# OCP_SOCKET_PRM register map
Vendor: Texas Instruments
Peripheral module from a debugger description file (folder TDA3x).
Registers are 32-bit, access per field, reset 0x0 unless marked. A register's access mark holds for its fields unless they carry their own. Offsets are as the file gives them; lines under a group give offsets from that group; [hi:lo] are bit positions; {n}, {i} and the like mark numbered series; 'fields as' and 'values as' point back to an identical list; <NAME> marks a mode.

## OCP_SOCKET_PRM
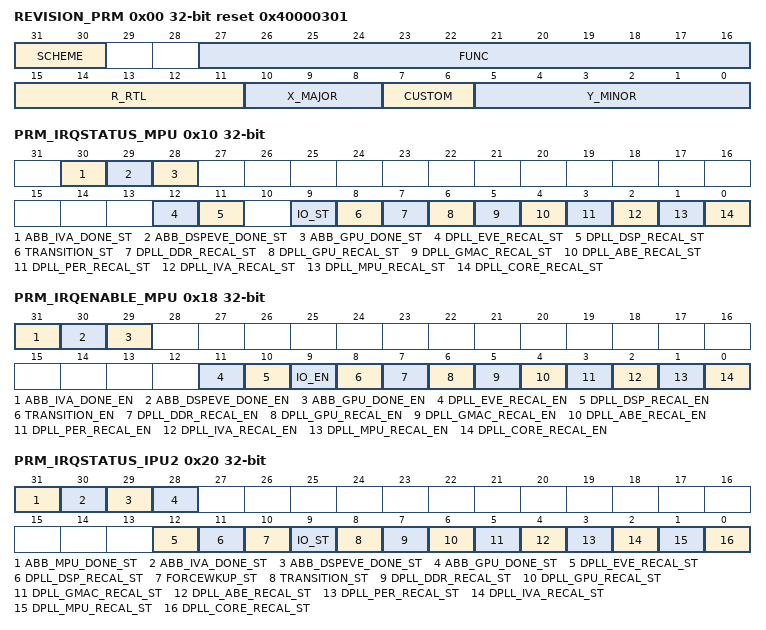
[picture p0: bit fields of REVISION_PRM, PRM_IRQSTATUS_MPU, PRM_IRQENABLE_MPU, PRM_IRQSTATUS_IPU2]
0x00 REVISION_PRM ro reset 0x40000301 — This register contains the IP revision code for the PRM part of the PRCM
  [31:30] SCHEME
  [27:16] FUNC — Function indicates a software compatible module family.
  [15:11] R_RTL — RTL Version (R)
  [10:8] X_MAJOR — Major Revision (X)
  [7:6] CUSTOM — Indicates a special version for a particular device.
    0=STANDARD (Non custom (standard) revision)
  [5:0] Y_MINOR — Minor Revision (Y)
0x10 PRM_IRQSTATUS_MPU — This register provides status on MPU interrupt events. Any event is logged independently of the corresponding IRQENABLE value. SW is required to clear a set bit by writing a '1' into the bit-position to be cleared.
  [all] fields
    0=IRQ_FAL (No interrupt); 1=IRQ_TRU (Interrupt is pending)
  [30] ABB_IVA_DONE_ST rw — IVA ABB mode change completion status. This status is set for both automatic transition upon a voltage transition, and OPP change (when OPP_CHANGE bit is cleared by hardware in PRM_ABBLDO_MM_CTRL register). It is cleared by SW.
  [29] ABB_DSPEVE_DONE_ST rw — DSPEVE ABB mode change completion status. This status is set for both automatic transition upon a voltage transition, and OPP change (when OPP_CHANGE bit is cleared by hardware in PRM_ABBLDO_MM_CTRL register). It is cleared by SW.
  [28] ABB_GPU_DONE_ST rw — GPU ABB mode change completion status. This status is set for both automatic transition upon a voltage transition, and OPP change (when OPP_CHANGE bit is cleared by hardware in PRM_ABBLDO_MM_CTRL register). It is cleared by SW.
  [12] DPLL_EVE_RECAL_ST rw — EVE DPLL recalibration interrupt status.
  [11] DPLL_DSP_RECAL_ST rw — DSP DPLL recalibration interrupt status.
  [9] IO_ST rw — IO pad event interrupt status.
  [8] TRANSITION_ST rw — Software supervised transition completed event interrupt status (any domain). Asserted upon completion of any clock domain force wakeup transition or upon completion of any power domain sleep transition with at least one enclosed clock domain configured in forced-sleep.
  [7] DPLL_DDR_RECAL_ST rw — DDR DPLL recalibration interrupt status.
  [6] DPLL_GPU_RECAL_ST rw — GPU DPLL recalibration interrupt status.
  [5] DPLL_GMAC_RECAL_ST rw — GMAC DPLL recalibration interrupt status.
  [4] DPLL_ABE_RECAL_ST rw — ABE DPLL recalibration interrupt status.
  [3] DPLL_PER_RECAL_ST rw — PER DPLL recalibration interrupt status.
  [2] DPLL_IVA_RECAL_ST rw — IVA DPLL recalibration interrupt status.
  [1] DPLL_MPU_RECAL_ST rw — MPU DPLL recalibration interrupt status.
  [0] DPLL_CORE_RECAL_ST rw — CORE DPLL recalibration interrupt status.
0x14 PRM_IRQSTATUS_MPU_2 — This register provides status on MPU interrupt events. Any event is logged independently of the corresponding IRQENABLE value. SW is required to clear a set bit by writing a '1' into the bit-position to be cleared.
  [7] ABB_MPU_DONE_ST rw — MPU ABB mode change completion status. This status is set for both automatic transition upon a voltage transition, and OPP change (when OPP_CHANGE bit is cleared by hardware in PRM_ABBLDO_MPU_CTRL register). It is cleared by SW.
    0=IRQ_FAL (No interrupt); 1=IRQ_TRU (Interrupt is pending)
0x18 PRM_IRQENABLE_MPU — This register is used to enable or disable MPU interrupt activation upon presence of corresponding IRQSTATUS bit.
  [31] ABB_IVA_DONE_EN rw — IVA ABB mode change done enable
    0=IRQ_FAL (No interrupt); 1=IRQ_TRU (Interrupt is pending)
  [30] ABB_DSPEVE_DONE_EN rw — DSPEVE ABB mode change done enable
    0=IRQ_FAL (No interrupt); 1=IRQ_TRU (Interrupt is pending)
  [29] ABB_GPU_DONE_EN rw — GPU ABB mode change done enable
    0=IRQ_FAL (No interrupt); 1=IRQ_TRU (Interrupt is pending)
  [11] DPLL_EVE_RECAL_EN rw — EVE DPLL recalibration interrupt enable
    0=IRQ_MSK (Interrupt is masked); 1=IRQ_EN (Interrupt is enabled)
  [10] DPLL_DSP_RECAL_EN rw — DSP DPLL recalibration interrupt enable
    values as DPLL_EVE_RECAL_EN
  [9] IO_EN rw — IO pad event interrupt enable
    values as DPLL_EVE_RECAL_EN
  [8] TRANSITION_EN rw — Software supervised transition completed event interrupt enable (any domain)
    values as DPLL_EVE_RECAL_EN
  [7] DPLL_DDR_RECAL_EN rw — DDR DPLL recalibration interrupt enable
    values as DPLL_EVE_RECAL_EN
  [6] DPLL_GPU_RECAL_EN rw — GPU DPLL recalibration interrupt enable
    values as DPLL_EVE_RECAL_EN
  [5] DPLL_GMAC_RECAL_EN rw — GMAC DPLL recalibration interrupt enable
    values as DPLL_EVE_RECAL_EN
  [4] DPLL_ABE_RECAL_EN rw — ABEDPLL recalibration interrupt enable
    values as DPLL_EVE_RECAL_EN
  [3] DPLL_PER_RECAL_EN rw — PER DPLL recalibration interrupt enable
    values as DPLL_EVE_RECAL_EN
  [2] DPLL_IVA_RECAL_EN rw — IVA DPLL recalibration interrupt enable
    values as DPLL_EVE_RECAL_EN
  [1] DPLL_MPU_RECAL_EN rw — MPU DPLL recalibration interrupt enable
    values as DPLL_EVE_RECAL_EN
  [0] DPLL_CORE_RECAL_EN rw — CORE DPLL recalibration interrupt enable
    values as DPLL_EVE_RECAL_EN
0x1C PRM_IRQENABLE_MPU_2 — This register is used to enable or disable MPU interrupt activation upon presence of corresponding IRQSTATUS bit.
  [7] ABB_MPU_DONE_EN rw — MPU ABB mode change done enable
    0=IRQ_FAL (No interrupt); 1=IRQ_TRU (Interrupt is pending)
0x20 PRM_IRQSTATUS_IPU2 — This register provides status on IPU2 interrupt events. Any event is logged independently of the corresponding IRQENABLE value. SW is required to clear a set bit by writing a '1' into the bit-position to be cleared.
  [all] fields
    0=IRQ_FAL (No interrupt); 1=IRQ_TRU (Interrupt is pending)
  [31] ABB_MPU_DONE_ST rw — MPU ABB mode change completion status. This status is set for both automatic transition upon a voltage transition, and OPP change (when OPP_CHANGE bit is cleared by hardware in PRM_ABBLDO_MM_CTRL register). It is cleared by SW.
  [30] ABB_IVA_DONE_ST rw — IVA ABB mode change completion status. This status is set for both automatic transition upon a voltage transition, and OPP change (when OPP_CHANGE bit is cleared by hardware in PRM_ABBLDO_MM_CTRL register). It is cleared by SW.
  [29] ABB_DSPEVE_DONE_ST rw — DSPEVE ABB mode change completion status. This status is set for both automatic transition upon a voltage transition, and OPP change (when OPP_CHANGE bit is cleared by hardware in PRM_ABBLDO_MM_CTRL register). It is cleared by SW.
  [28] ABB_GPU_DONE_ST rw — GPU ABB mode change completion status. This status is set for both automatic transition upon a voltage transition, and OPP change (when OPP_CHANGE bit is cleared by hardware in PRM_ABBLDO_MM_CTRL register). It is cleared by SW.
  [12] DPLL_EVE_RECAL_ST rw — EVE DPLL recalibration interrupt status.
  [11] DPLL_DSP_RECAL_ST rw — DSP DPLL recalibration interrupt status.
  [10] FORCEWKUP_ST rw — IPU domain software supervised wakeup transition completed event interrupt status.
  [9] IO_ST rw — IO pad event interrupt status.
  [8] TRANSITION_ST rw — Software supervised transition completed event interrupt status (any domain). Asserted upon completion of any clock domain force wakeup transition or upon completion of any power domain sleep transition with at least one enclosed clock domain configured in forced-sleep.
  [7] DPLL_DDR_RECAL_ST rw — DDR DPLL recalibration interrupt status.
  [6] DPLL_GPU_RECAL_ST rw — GPU DPLL recalibration interrupt status.
  [5] DPLL_GMAC_RECAL_ST rw — GMAC DPLL recalibration interrupt status.
  [4] DPLL_ABE_RECAL_ST rw — ABE DPLL recalibration interrupt status.
  [3] DPLL_PER_RECAL_ST rw — PER DPLL recalibration interrupt status.
  [2] DPLL_IVA_RECAL_ST rw — IVA DPLL recalibration interrupt status.
  [1] DPLL_MPU_RECAL_ST rw — MPU DPLL recalibration interrupt status.
  [0] DPLL_CORE_RECAL_ST rw — CORE DPLL recalibration interrupt status.
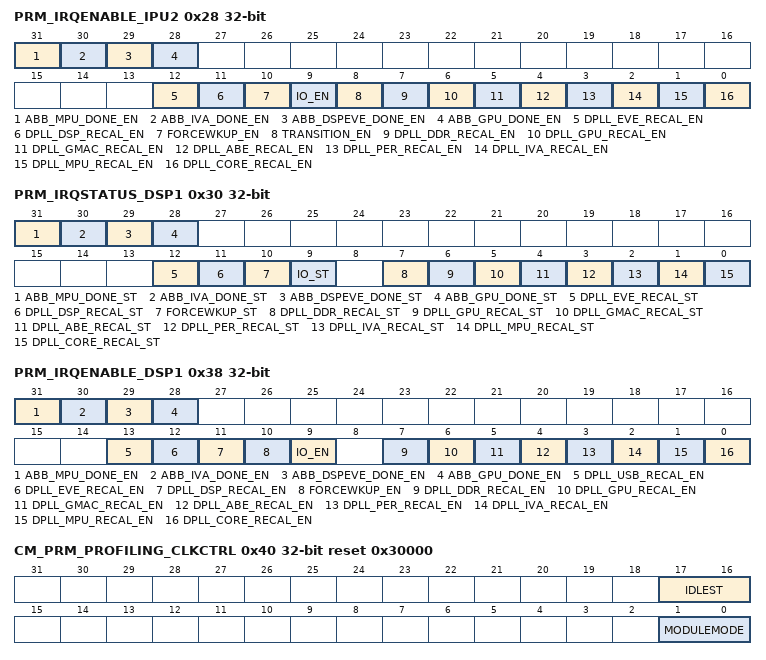
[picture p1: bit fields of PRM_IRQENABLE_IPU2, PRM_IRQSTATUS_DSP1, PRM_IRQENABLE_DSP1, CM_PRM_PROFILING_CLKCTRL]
0x28 PRM_IRQENABLE_IPU2 — This register is used to enable or disable IPU2 interrupt activation upon presence of corresponding IRQSTATUS bit.
  [31] ABB_MPU_DONE_EN rw — MPU ABB mode change done enable
    0=IRQ_FAL (No interrupt); 1=IRQ_TRU (Interrupt is pending)
  [30] ABB_IVA_DONE_EN rw — IVA ABB mode change done enable
    0=IRQ_FAL (No interrupt); 1=IRQ_TRU (Interrupt is pending)
  [29] ABB_DSPEVE_DONE_EN rw — DSPEVE ABB mode change done enable
    0=IRQ_FAL (No interrupt); 1=IRQ_TRU (Interrupt is pending)
  [28] ABB_GPU_DONE_EN rw — GPU ABB mode change done enable
    0=IRQ_FAL (No interrupt); 1=IRQ_TRU (Interrupt is pending)
  [12] DPLL_EVE_RECAL_EN rw — EVE DPLL recalibration interrupt enable
    values as PRM_IRQENABLE_MPU.DPLL_EVE_RECAL_EN
  [11] DPLL_DSP_RECAL_EN rw — DSP DPLL recalibration interrupt enable
    values as PRM_IRQENABLE_MPU.DPLL_EVE_RECAL_EN
  [10] FORCEWKUP_EN rw — IPU domain software supervised wakeup transition completed event interrupt enable.
    values as PRM_IRQENABLE_MPU.DPLL_EVE_RECAL_EN
  [9] IO_EN rw — IO pad event interrupt enable
    values as PRM_IRQENABLE_MPU.DPLL_EVE_RECAL_EN
  [8] TRANSITION_EN rw — Software supervised transition completed event interrupt enable (any domain)
    values as PRM_IRQENABLE_MPU.DPLL_EVE_RECAL_EN
  [7] DPLL_DDR_RECAL_EN rw — DDR DPLL recalibration interrupt enable
    values as PRM_IRQENABLE_MPU.DPLL_EVE_RECAL_EN
  [6] DPLL_GPU_RECAL_EN rw — GPU DPLL recalibration interrupt enable
    values as PRM_IRQENABLE_MPU.DPLL_EVE_RECAL_EN
  [5] DPLL_GMAC_RECAL_EN rw — GMAC DPLL recalibration interrupt enable
    values as PRM_IRQENABLE_MPU.DPLL_EVE_RECAL_EN
  [4] DPLL_ABE_RECAL_EN rw — ABEDPLL recalibration interrupt enable
    values as PRM_IRQENABLE_MPU.DPLL_EVE_RECAL_EN
  [3] DPLL_PER_RECAL_EN rw — PER DPLL recalibration interrupt enable
    values as PRM_IRQENABLE_MPU.DPLL_EVE_RECAL_EN
  [2] DPLL_IVA_RECAL_EN rw — IVA DPLL recalibration interrupt enable
    values as PRM_IRQENABLE_MPU.DPLL_EVE_RECAL_EN
  [1] DPLL_MPU_RECAL_EN rw — MPU DPLL recalibration interrupt enable
    values as PRM_IRQENABLE_MPU.DPLL_EVE_RECAL_EN
  [0] DPLL_CORE_RECAL_EN rw — CORE DPLL recalibration interrupt enable
    values as PRM_IRQENABLE_MPU.DPLL_EVE_RECAL_EN
0x30 PRM_IRQSTATUS_DSP1 — This register provides status on DSP1 interrupt events. Any event is logged independently of the corresponding IRQENABLE value. SW is required to clear a set bit by writing a '1' into the bit-position to be cleared.
  [all] fields
    0=IRQ_FAL (No interrupt); 1=IRQ_TRU (Interrupt is pending)
  [31] ABB_MPU_DONE_ST rw — MPU ABB mode change completion status. This status is set for both automatic transition upon a voltage transition, and OPP change (when OPP_CHANGE bit is cleared by hardware in PRM_ABBLDO_MM_CTRL register). It is cleared by SW.
  [30] ABB_IVA_DONE_ST rw — IVA ABB mode change completion status. This status is set for both automatic transition upon a voltage transition, and OPP change (when OPP_CHANGE bit is cleared by hardware in PRM_ABBLDO_MM_CTRL register). It is cleared by SW.
  [29] ABB_DSPEVE_DONE_ST rw — DSPEVE ABB mode change completion status. This status is set for both automatic transition upon a voltage transition, and OPP change (when OPP_CHANGE bit is cleared by hardware in PRM_ABBLDO_MM_CTRL register). It is cleared by SW.
  [28] ABB_GPU_DONE_ST rw — GPU ABB mode change completion status. This status is set for both automatic transition upon a voltage transition, and OPP change (when OPP_CHANGE bit is cleared by hardware in PRM_ABBLDO_MM_CTRL register). It is cleared by SW.
  [12] DPLL_EVE_RECAL_ST rw — EVE DPLL recalibration interrupt status.
  [11] DPLL_DSP_RECAL_ST rw — DSP DPLL recalibration interrupt status.
  [10] FORCEWKUP_ST rw — IPU domain software supervised wakeup transition completed event interrupt status.
  [9] IO_ST rw — IO pad event interrupt status.
  [7] DPLL_DDR_RECAL_ST rw — DDR DPLL recalibration interrupt status.
  [6] DPLL_GPU_RECAL_ST rw — GPU DPLL recalibration interrupt status.
  [5] DPLL_GMAC_RECAL_ST rw — GMAC DPLL recalibration interrupt status.
  [4] DPLL_ABE_RECAL_ST rw — ABE DPLL recalibration interrupt status.
  [3] DPLL_PER_RECAL_ST rw — PER DPLL recalibration interrupt status.
  [2] DPLL_IVA_RECAL_ST rw — IVA DPLL recalibration interrupt status.
  [1] DPLL_MPU_RECAL_ST rw — MPU DPLL recalibration interrupt status.
  [0] DPLL_CORE_RECAL_ST rw — CORE DPLL recalibration interrupt status.
0x38 PRM_IRQENABLE_DSP1 — This register is used to enable or disable DSP1 interrupt activation upon presence of corresponding IRQSTATUS bit.
  [31] ABB_MPU_DONE_EN rw — MPU ABB mode change done enable
    0=IRQ_FAL (No interrupt); 1=IRQ_TRU (Interrupt is pending)
  [30] ABB_IVA_DONE_EN rw — IVA ABB mode change done enable
    0=IRQ_FAL (No interrupt); 1=IRQ_TRU (Interrupt is pending)
  [29] ABB_DSPEVE_DONE_EN rw — DSPEVE ABB mode change done enable
    0=IRQ_FAL (No interrupt); 1=IRQ_TRU (Interrupt is pending)
  [28] ABB_GPU_DONE_EN rw — GPU ABB mode change done enable
    0=IRQ_FAL (No interrupt); 1=IRQ_TRU (Interrupt is pending)
  [13] DPLL_USB_RECAL_EN rw — USB DPLL recalibration interrupt enable
    values as PRM_IRQENABLE_MPU.DPLL_EVE_RECAL_EN
  [12] DPLL_EVE_RECAL_EN rw — EVE DPLL recalibration interrupt enable
    values as PRM_IRQENABLE_MPU.DPLL_EVE_RECAL_EN
  [11] DPLL_DSP_RECAL_EN rw — DSP DPLL recalibration interrupt enable
    values as PRM_IRQENABLE_MPU.DPLL_EVE_RECAL_EN
  [10] FORCEWKUP_EN rw — IPU domain software supervised wakeup transition completed event interrupt enable.
    values as PRM_IRQENABLE_MPU.DPLL_EVE_RECAL_EN
  [9] IO_EN rw — IO pad event interrupt enable
    values as PRM_IRQENABLE_MPU.DPLL_EVE_RECAL_EN
  [7] DPLL_DDR_RECAL_EN rw — DDR DPLL recalibration interrupt enable
    values as PRM_IRQENABLE_MPU.DPLL_EVE_RECAL_EN
  [6] DPLL_GPU_RECAL_EN rw — GPU DPLL recalibration interrupt enable
    values as PRM_IRQENABLE_MPU.DPLL_EVE_RECAL_EN
  [5] DPLL_GMAC_RECAL_EN rw — GMAC DPLL recalibration interrupt enable
    values as PRM_IRQENABLE_MPU.DPLL_EVE_RECAL_EN
  [4] DPLL_ABE_RECAL_EN rw — ABEDPLL recalibration interrupt enable
    values as PRM_IRQENABLE_MPU.DPLL_EVE_RECAL_EN
  [3] DPLL_PER_RECAL_EN rw — PER DPLL recalibration interrupt enable
    values as PRM_IRQENABLE_MPU.DPLL_EVE_RECAL_EN
  [2] DPLL_IVA_RECAL_EN rw — IVA DPLL recalibration interrupt enable
    values as PRM_IRQENABLE_MPU.DPLL_EVE_RECAL_EN
  [1] DPLL_MPU_RECAL_EN rw — MPU DPLL recalibration interrupt enable
    values as PRM_IRQENABLE_MPU.DPLL_EVE_RECAL_EN
  [0] DPLL_CORE_RECAL_EN rw — CORE DPLL recalibration interrupt enable
    values as PRM_IRQENABLE_MPU.DPLL_EVE_RECAL_EN
0x40 CM_PRM_PROFILING_CLKCTRL reset 0x30000 — This register manages the PRM_PROFILING clock. [warm reset insensitive]
  [17:16] IDLEST ro — Module idle status
    0=FUNC (Module is fully functional); 1=TRANS (Module is performing transition: wakeup, or sleep, or sleep abortion); 2=IDLE (Module is in Idle); 3=DISABLE (Module is disabled)
  [1:0] MODULEMODE rw — Control the way mandatory clocks are managed.
    0=DISABLED (Module is disabled by SW. OCP configuration port is not accessible.); 1=AUTO (Module is managed automatically by HW along with EMU domain. OCP configuration port is accessible only when EMU domain is on.)
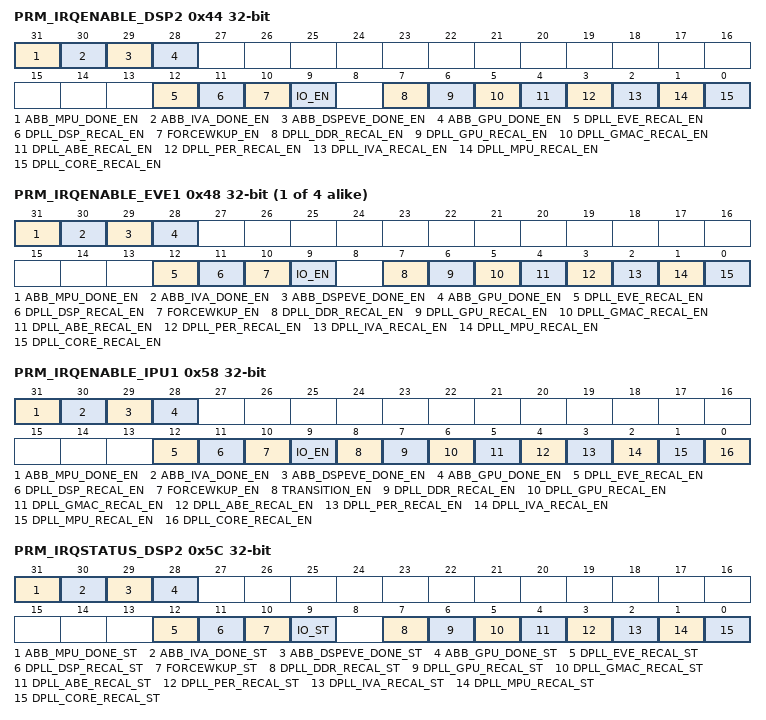
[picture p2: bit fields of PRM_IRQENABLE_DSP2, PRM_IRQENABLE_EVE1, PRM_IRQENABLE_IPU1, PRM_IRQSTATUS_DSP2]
0x44 PRM_IRQENABLE_DSP2 — This register is used to enable or disable DSP2 interrupt activation upon presence of corresponding IRQSTATUS bit.
  [31] ABB_MPU_DONE_EN rw — MPU ABB mode change done enable
    0=IRQ_FAL (No interrupt); 1=IRQ_TRU (Interrupt is pending)
  [30] ABB_IVA_DONE_EN rw — IVA ABB mode change done enable
    0=IRQ_FAL (No interrupt); 1=IRQ_TRU (Interrupt is pending)
  [29] ABB_DSPEVE_DONE_EN rw — DSPEVE ABB mode change done enable
    0=IRQ_FAL (No interrupt); 1=IRQ_TRU (Interrupt is pending)
  [28] ABB_GPU_DONE_EN rw — GPU ABB mode change done enable
    0=IRQ_FAL (No interrupt); 1=IRQ_TRU (Interrupt is pending)
  [12] DPLL_EVE_RECAL_EN rw — EVE DPLL recalibration interrupt enable
    values as PRM_IRQENABLE_MPU.DPLL_EVE_RECAL_EN
  [11] DPLL_DSP_RECAL_EN rw — DSP DPLL recalibration interrupt enable
    values as PRM_IRQENABLE_MPU.DPLL_EVE_RECAL_EN
  [10] FORCEWKUP_EN rw — IPU domain software supervised wakeup transition completed event interrupt enable.
    values as PRM_IRQENABLE_MPU.DPLL_EVE_RECAL_EN
  [9] IO_EN rw — IO pad event interrupt enable
    values as PRM_IRQENABLE_MPU.DPLL_EVE_RECAL_EN
  [7] DPLL_DDR_RECAL_EN rw — DDR DPLL recalibration interrupt enable
    values as PRM_IRQENABLE_MPU.DPLL_EVE_RECAL_EN
  [6] DPLL_GPU_RECAL_EN rw — GPU DPLL recalibration interrupt enable
    values as PRM_IRQENABLE_MPU.DPLL_EVE_RECAL_EN
  [5] DPLL_GMAC_RECAL_EN rw — GMAC DPLL recalibration interrupt enable
    values as PRM_IRQENABLE_MPU.DPLL_EVE_RECAL_EN
  [4] DPLL_ABE_RECAL_EN rw — ABEDPLL recalibration interrupt enable
    values as PRM_IRQENABLE_MPU.DPLL_EVE_RECAL_EN
  [3] DPLL_PER_RECAL_EN rw — PER DPLL recalibration interrupt enable
    values as PRM_IRQENABLE_MPU.DPLL_EVE_RECAL_EN
  [2] DPLL_IVA_RECAL_EN rw — IVA DPLL recalibration interrupt enable
    values as PRM_IRQENABLE_MPU.DPLL_EVE_RECAL_EN
  [1] DPLL_MPU_RECAL_EN rw — MPU DPLL recalibration interrupt enable
    values as PRM_IRQENABLE_MPU.DPLL_EVE_RECAL_EN
  [0] DPLL_CORE_RECAL_EN rw — CORE DPLL recalibration interrupt enable
    values as PRM_IRQENABLE_MPU.DPLL_EVE_RECAL_EN
{0x44+4i} PRM_IRQENABLE_EVE{i} (i=1..4) — This register is used to enable or disable EVE{i} interrupt activation upon presence of corresponding IRQSTATUS bit.
  fields as PRM_IRQENABLE_DSP2
0x58 PRM_IRQENABLE_IPU1 — This register is used to enable or disable IPU1 interrupt activation upon presence of corresponding IRQSTATUS bit.
  fields as PRM_IRQENABLE_IPU2
0x5C PRM_IRQSTATUS_DSP2 — This register provides status on DSP interrupt events. Any event is logged independently of the corresponding IRQENABLE value. SW is required to clear a set bit by writing a '1' into the bit-position to be cleared.
  fields as PRM_IRQSTATUS_DSP1
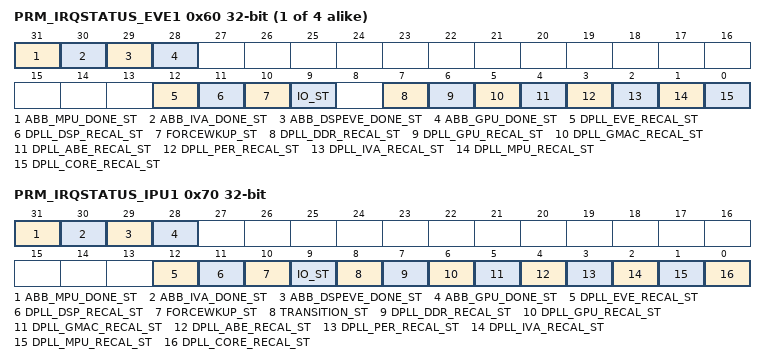
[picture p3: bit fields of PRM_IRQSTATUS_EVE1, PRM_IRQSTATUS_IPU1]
{0x5C+4i} PRM_IRQSTATUS_EVE{i} (i=1..4) — This register provides status on EVE interrupt events. Any event is logged independently of the corresponding IRQENABLE value. SW is required to clear a set bit by writing a '1' into the bit-position to be cleared.
  fields as PRM_IRQSTATUS_DSP1
0x70 PRM_IRQSTATUS_IPU1 — This register provides status on IPU1 interrupt events. Any event is logged independently of the corresponding IRQENABLE value. SW is required to clear a set bit by writing a '1' into the bit-position to be cleared.
  fields as PRM_IRQSTATUS_IPU2
{0xE0+4i} PRM_DEBUG_CFG{i} (i=1..3) — This register is used to configure the PRM's 32-bit debug output. There is one 7-bit source select field for selecting from a shared set of 8-bit internal signal blocks per byte. The signals included in each block are specified in the PRCM integration specification. [warm reset insensitive]
  [8:0] SEL{i} rw — Internal signal block select for debug word byte-{i}
0xF0 PRM_DEBUG_CFG — This register is used to configure the PRM's 32-bit debug output. There is one 7-bit source select field for selecting from a shared set of 8-bit internal signal blocks per byte. The signals included in each block are specified in the PRCM integration specification. [warm reset insensitive]
  [8:0] SEL0 rw — Internal signal block select for debug word byte-0
0xF4 PRM_DEBUG_OUT ro — This register is used to monitor the PRM's 32 bit HEDEBUG BUS [warm reset insensitive]
  [31:0] OUTPUT — HW DEBUG OUTPUT
